# STM32MP153x register map
File version: 1.0
Registers are 32-bit, read-write, reset 0x0 unless marked. A register's access mark holds for its fields unless they carry their own. Offsets are from the block's base; [hi:lo] are bit positions; {n}, {i} and the like mark numbered series.

## ADC_common — Analog-to-Digital Converter
Base 0x48003300
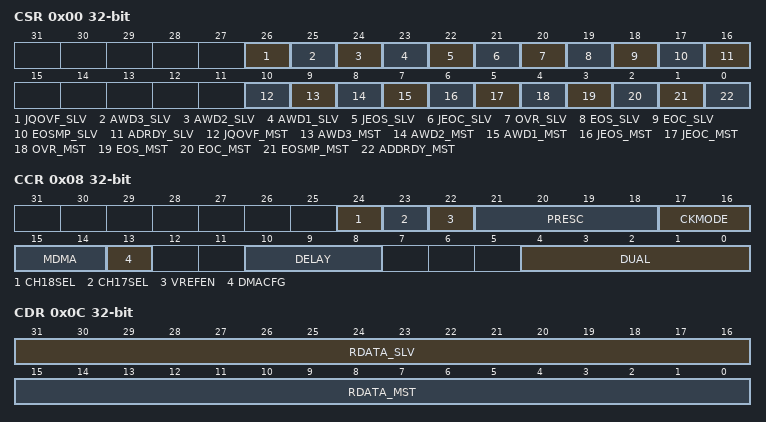
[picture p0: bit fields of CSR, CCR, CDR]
0x00 CSR ro — ADC Common status register
  [26] JQOVF_SLV, [25] AWD3_SLV, [24] AWD2_SLV, [23] AWD1_SLV, [22] JEOS_SLV, [21] JEOC_SLV, [20] OVR_SLV, [19] EOS_SLV, [18] EOC_SLV, [17] EOSMP_SLV, [16] ADRDY_SLV, [10] JQOVF_MST, [9] AWD3_MST, [8] AWD2_MST, [7] AWD1_MST, [6] JEOS_MST, [5] JEOC_MST, [4] OVR_MST, [3] EOS_MST, [2] EOC_MST, [1] EOSMP_MST, [0] ADDRDY_MST
0x08 CCR — ADC common control register
  [24] CH18SEL
  [23] CH17SEL
  [22] VREFEN — VREFINT enable
  [21:18] PRESC — ADC prescaler
  [17:16] CKMODE — ADC clock mode
  [15:14] MDMA
  [13] DMACFG
  [10:8] DELAY
  [4:0] DUAL
0x0C CDR ro — Common regular data register for dual mode
  [31:16] RDATA_SLV, [15:0] RDATA_MST
0x10 CDR2 ro — Common regular data register for dual mode
  [31:0] RDATA_ALT

## DCMI
Base 0x4C006000
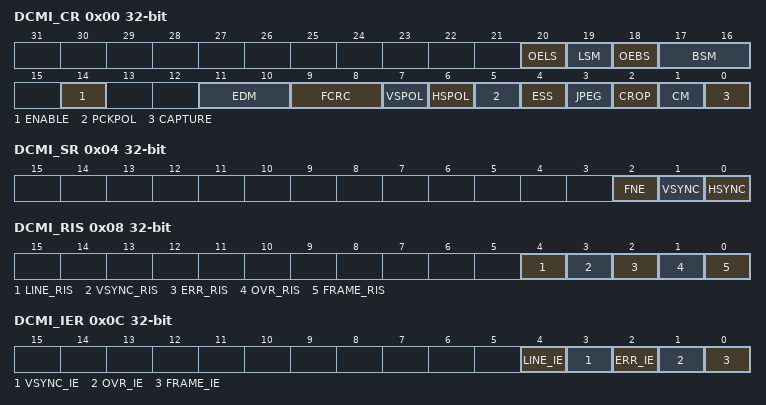
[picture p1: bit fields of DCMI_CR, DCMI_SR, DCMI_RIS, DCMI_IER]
0x00 DCMI_CR — DCMI control register
  [20] OELS, [19] LSM, [18] OEBS, [17:16] BSM, [14] ENABLE, [11:10] EDM, [9:8] FCRC, [7] VSPOL, [6] HSPOL, [5] PCKPOL, [4] ESS, [3] JPEG, [2] CROP, [1] CM, [0] CAPTURE
0x04 DCMI_SR ro — DCMI status register
  [2] FNE, [1] VSYNC, [0] HSYNC
0x08 DCMI_RIS ro — DCMI_RIS gives the raw interrupt status and is accessible in read only. When read, this register returns the status of the corresponding interrupt before masking with the DCMI_IER register value.
  [4] LINE_RIS, [3] VSYNC_RIS, [2] ERR_RIS, [1] OVR_RIS, [0] FRAME_RIS
0x0C DCMI_IER — The DCMI_IER register is used to enable interrupts. When one of the DCMI_IER bits is set, the corresponding interrupt is enabled. This register is accessible in both read and write.
  [4] LINE_IE, [3] VSYNC_IE, [2] ERR_IE, [1] OVR_IE, [0] FRAME_IE
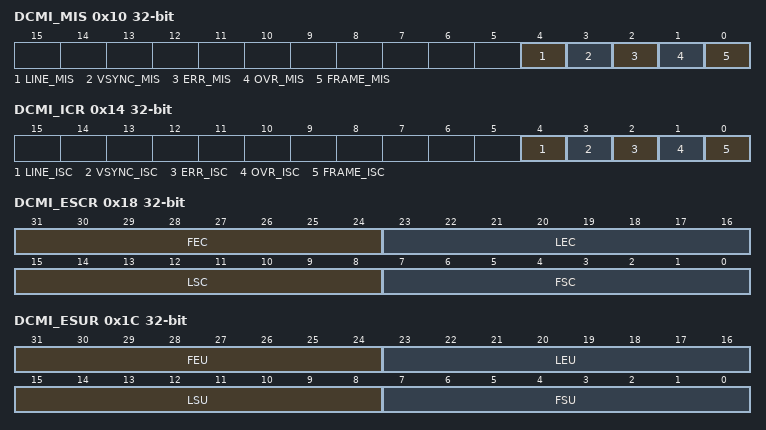
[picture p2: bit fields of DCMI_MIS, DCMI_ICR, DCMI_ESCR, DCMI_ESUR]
0x10 DCMI_MIS ro — This DCMI_MIS register is a read-only register. When read, it returns the current masked status value (depending on the value in DCMI_IER) of the corresponding interrupt. A bit in this register is set if the corresponding enable bit in DCMI_IER is set and the corresponding bit in DCMI_RIS is set.
  [4] LINE_MIS, [3] VSYNC_MIS, [2] ERR_MIS, [1] OVR_MIS, [0] FRAME_MIS
0x14 DCMI_ICR wo — The DCMI_ICR register is write-only.
  [4] LINE_ISC, [3] VSYNC_ISC, [2] ERR_ISC, [1] OVR_ISC, [0] FRAME_ISC
0x18 DCMI_ESCR — DCMI embedded synchronization code register
  [31:24] FEC, [23:16] LEC, [15:8] LSC, [7:0] FSC
0x1C DCMI_ESUR — DCMI embedded synchronization unmask register
  [31:24] FEU, [23:16] LEU, [15:8] LSU, [7:0] FSU
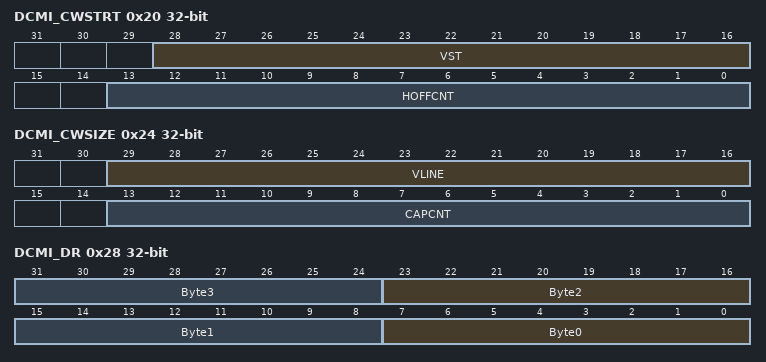
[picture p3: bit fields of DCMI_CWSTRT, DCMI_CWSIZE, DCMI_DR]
0x20 DCMI_CWSTRT — DCMI crop window start
  [28:16] VST, [13:0] HOFFCNT
0x24 DCMI_CWSIZE — DCMI crop window size
  [29:16] VLINE, [13:0] CAPCNT
0x28 DCMI_DR ro — DCMI data register
  [8n+7:8n] Byte{n} (n=0..3)

## DAC1
Base 0x40017000
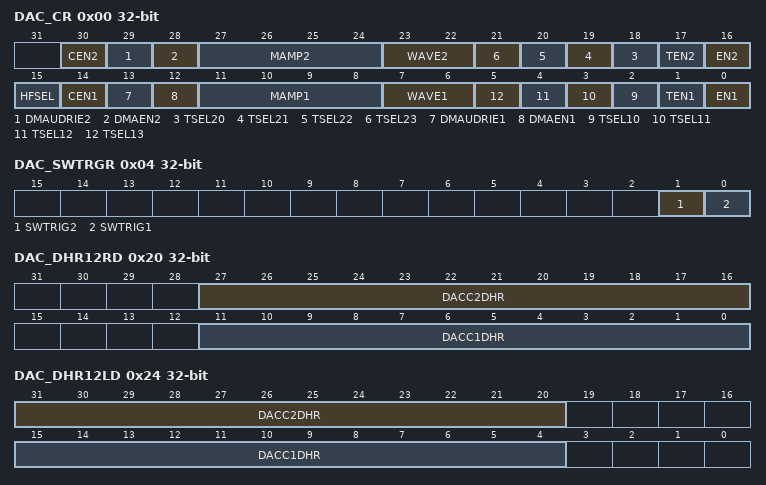
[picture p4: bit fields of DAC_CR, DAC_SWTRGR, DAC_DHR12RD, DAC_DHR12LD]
0x00 DAC_CR — DAC control register
  [30] CEN2, [29] DMAUDRIE2, [28] DMAEN2, [27:24] MAMP2, [23:22] WAVE2, [n-2] TSEL{n} (n=20..23), [17] TEN2, [16] EN2, [15] HFSEL, [14] CEN1, [13] DMAUDRIE1, [12] DMAEN1, [11:8] MAMP1, [7:6] WAVE1, [n-8] TSEL{n} (n=10..13), [1] TEN1, [0] EN1
0x04 DAC_SWTRGR wo — DAC software trigger register
  [1] SWTRIG2, [0] SWTRIG1
0x08 DAC_DHR12R1 — DAC channel1 12-bit right-aligned data holding register
  [11:0] DACC1DHR
0x0C DAC_DHR12L1 — DAC channel1 12-bit left aligned data holding register
  [15:4] DACC1DHR
0x10 DAC_DHR8R1 — DAC channel1 8-bit right aligned data holding register
  [7:0] DACC1DHR
0x14 DAC_DHR12R2 — This register is available only on dual-channel DACs. Refer to Section29.3: DAC implementation.
  [11:0] DACC2DHR
0x18 DAC_DHR12L2 — This register is available only on dual-channel DACs. Refer to Section29.3: DAC implementation.
  [15:4] DACC2DHR
0x1C DAC_DHR8R2 — This register is available only on dual-channel DACs. Refer to Section29.3: DAC implementation.
  [7:0] DACC2DHR
0x20 DAC_DHR12RD — Dual DAC 12-bit right-aligned data holding register
  [27:16] DACC2DHR, [11:0] DACC1DHR
0x24 DAC_DHR12LD — Dual DAC 12-bit left aligned data holding register
  [31:20] DACC2DHR, [15:4] DACC1DHR
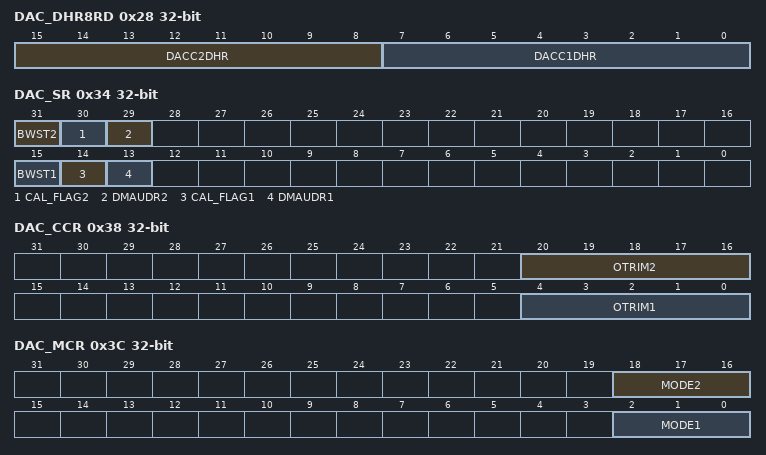
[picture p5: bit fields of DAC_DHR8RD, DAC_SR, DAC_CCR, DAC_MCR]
0x28 DAC_DHR8RD — Dual DAC 8-bit right aligned data holding register
  [15:8] DACC2DHR, [7:0] DACC1DHR
0x2C DAC_DOR1 ro — DAC channel1 data output register
  [11:0] DACC1DOR
0x30 DAC_DOR2 ro — This register is available only on dual-channel DACs. Refer to Section29.3: DAC implementation.
  [11:0] DACC2DOR
0x34 DAC_SR access per field — DAC status register
  [31] BWST2 ro, [30] CAL_FLAG2 ro, [29] DMAUDR2 rw, [15] BWST1 ro, [14] CAL_FLAG1 ro, [13] DMAUDR1 rw
0x38 DAC_CCR — DAC calibration control register
  [20:16] OTRIM2, [4:0] OTRIM1
0x3C DAC_MCR — DAC mode control register
  [18:16] MODE2, [2:0] MODE1
0x40 DAC_SHSR1 — DAC channel 1 sample and hold sample time register
  [9:0] TSAMPLE1
0x44 DAC_SHSR2 — This register is available only on dual-channel DACs. Refer to Section29.3: DAC implementation.
  [9:0] TSAMPLE2
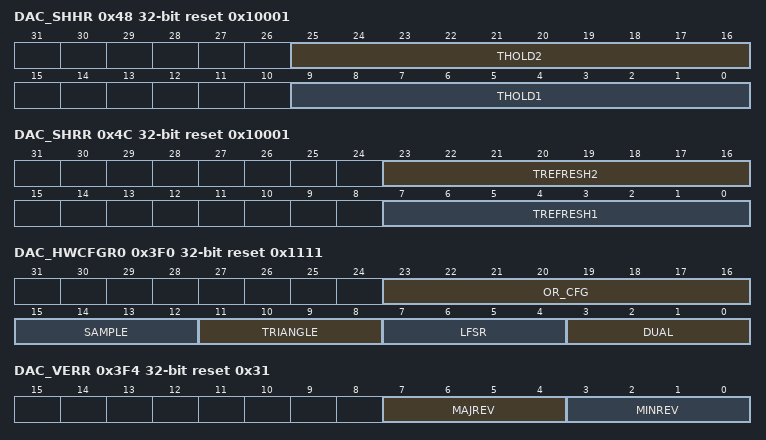
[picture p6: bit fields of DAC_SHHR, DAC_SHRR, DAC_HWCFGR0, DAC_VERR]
0x48 DAC_SHHR reset 0x10001 — DAC sample and hold time register
  [25:16] THOLD2, [9:0] THOLD1
0x4C DAC_SHRR reset 0x10001 — DAC sample and hold refresh time register
  [23:16] TREFRESH2, [7:0] TREFRESH1
0x3F0 DAC_HWCFGR0 ro reset 0x1111 — DAC IP hardware configuration register
  [23:16] OR_CFG, [15:12] SAMPLE, [11:8] TRIANGLE, [7:4] LFSR, [3:0] DUAL
0x3F4 DAC_VERR ro reset 0x31 — No
  [7:4] MAJREV, [3:0] MINREV
0x3F8 DAC_IPIDR ro reset 0x110011 — No
  [31:0] ID
0x3FC DAC_SIDR ro reset 0xA3C5DD01 — No
  [31:0] SID
